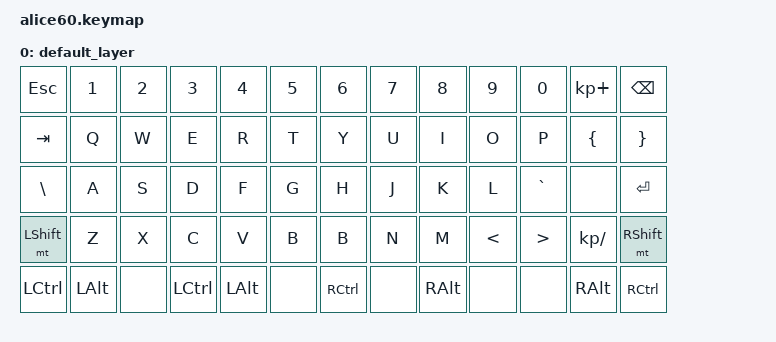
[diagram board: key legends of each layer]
/*
 * Copyright (c) 2020 The ZMK Contributors
 *
 * SPDX-License-Identifier: MIT
 */

#include <behaviors.dtsi>
#include <dt-bindings/zmk/keys.h>
#include <dt-bindings/zmk/rgb.h>
#include <dt-bindings/zmk/bt.h>
#include <dt-bindings/zmk/outputs.h>
#include <dt-bindings/zmk/ext_power.h>
#include <dt-bindings/zmk/mouse.h>

/ {
	keymap0: keymap {
		compatible = "zmk,keymap";

		default_layer {
            // | --- |   Q   |   W   |   E   |   R   |   T   |   Y   |   U   |   I   |   O   |   P   |  --- |
            // | --- |   A   |   S   |   D   |   F   |   G   |   H   |   J   |   K   |   L   |  Ent  |  --- |
            // | --- |   Z   |   X   |   C   |   V   |   B   |   N   |   M   | 3,Spc |  Del  |  BS   |  --- |
            // | --- |  ---  |  ---  | LCtrl | MO(1) | LSht  |  LAlt | MO(2) | LWin  |  ---  |  ---  |  --- | 
            // RC(0,0) RC(0,1) RC(0,2) RC(0,3) RC(0,4) RC(0,5) RC(0,6) RC(0,7) RC(0,8) RC(0,9) RC(0,10) RC(0,11) RC(0,12) 
            // RC(1,0) RC(1,1) RC(1,2) RC(1,3) RC(1,4) RC(1,5) RC(1,6) RC(1,7) RC(1,8) RC(1,9) RC(1,10) RC(1,11) RC(1,12) 
            // RC(2,0) RC(2,1) RC(2,2) RC(2,3) RC(2,4) RC(2,5) RC(2,6) RC(2,7) RC(2,8) RC(2,9) RC(2,10)          RC(2,12) 
            // RC(3,0) RC(3,1) RC(3,2) RC(3,3) RC(3,4) RC(3,5) RC(3,6) RC(3,7) RC(3,8) RC(3,9) RC(3,10) RC(3,11) RC(3,12)
            // RC(4,0) RC(4,1)         RC(4,3) RC(4,4)         RC(4,6)         RC(4,8)                  RC(4,11) RC(4,12)
            bindings = <
            &kp ESC     &kp N1   &kp N2    &kp N3       &kp N4      &kp N5      &kp N6      &kp N7      &kp N8      &kp N9      &kp N0      &kp KP_PLUS     &kp BSPC
            &kp TAB     &kp Q    &kp W     &kp E        &kp R       &kp T       &kp Y       &kp U       &kp I       &kp O       &kp P       &kp LBRC        &kp RBRC
            &kp BSLH    &kp A    &kp S     &kp D        &kp F       &kp G       &kp H       &kp J       &kp K       &kp L       &kp GRAVE   &none           &kp ENTER
            &mt LSHFT   &kp Z    &kp X     &kp C        &kp V       &kp B       &kp B       &kp N       &kp M       &kp LT      &kp GT      &kp KP_SLASH    &mt RSHFT
            &kp LCTRL   &kp LALT &none     &kp LCTRL    &kp LALT    &none       &kp RCTRL   &none       &kp RALT    &none       &none       &kp RALT        &kp RCTRL
            >;
		};
	};
};
